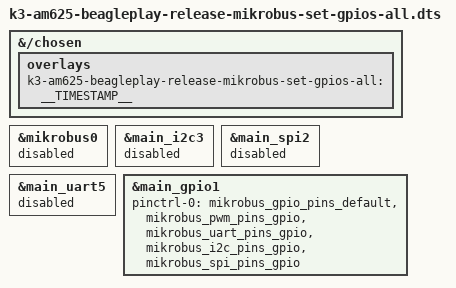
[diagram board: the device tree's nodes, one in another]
// SPDX-License-Identifier: GPL-2.0
/*
 * DT Overlay for disabling mikrobus device and reassigning pins to default options
 *
 * Copyright (C) 2023 Texas Instruments Incorporated - https://www.ti.com/
 *
 * Signal maps (GPIO Signal names to GPIO Signal (GPIO1 == 601000.gpio)
 * MIKROBUS_GPIO1_7  -> GPIO1_7
 * MIKROBUS_GPIO1_8  -> GPIO1_8
 * MIKROBUS_GPIO1_9  -> GPIO1_9
 * MIKROBUS_GPIO1_10 -> GPIO1_10
 * MIKROBUS_GPIO1_11 -> GPIO1_11
 * MIKROBUS_GPIO1_12 -> GPIO1_12
 * MIKROBUS_W1_GPIO0 -> GPIO1_13
 * MIKROBUS_GPIO1_14 -> GPIO1_14
 * MIKROBUS_GPIO1_22 -> GPIO1_22
 * MIKROBUS_GPIO1_23 -> GPIO1_23
 * MIKROBUS_GPIO1_24 -> GPIO1_24
 * MIKROBUS_GPIO1_25 -> GPIO1_25
 * MIKROBUS_GPIO1_22 -> GPIO1_22
 * MIKROBUS_GPIO1_23 -> GPIO1_23
 * MIKROBUS_GPIO1_24 -> GPIO1_24
 * MIKROBUS_GPIO1_25 -> GPIO1_25
 *
 * Mapped to Signals, these look as follows ("GPIO Mode" is set by this overlay):
 *
 * GPIO       Native        Pin                                    Pin   Native         GPIO
 * Mode       Function      Num     Legend              Legend     Num   Function       Mode
 * |                |        |       |                     |        |       |           |
 * |                |        |       v                     v        |       |           |
 * v                v        v     +--------------------------+     v       v           v
 * GPIO1_10  GPIO1_10  ------9-----+ AN                   PWM +-----8------ GPIO1_11    GPIO1_11
 *                                 |                          |
 * GPIO1_12  GPIO1_12  ------10----+ RST                  INT +-----7------ GPIO1_9     GPIO1_9
 *                                 |                          |
 * GPIO1_13  SPI2_CS0  ------11----+ CS                    RX +-----6------ UART5_RXD   GPIO1_24
 *                                 |                          |
 * GPIO1_14  SPI2_CLK  ------12----+ SCK                   TX +-----5------ UART5_TXD   GPIO1_25
 *                                 |                          |
 * GPIO1_7   SPI2_D0   ------13----+ MISO                 SCL +-----4------ I2C3_SCL    GPIO1_22
 *                                 |                          |
 * GPIO1_8   SPI2_D1   ------14----+ MOSI                 SDA +-----3------ I2C3_SDA    GPIO1_23
 *                                 |                          |
 *                     ------15----+ +3.3V                +5V +-----2------
 *                                 |                          |
 *                     ------16----+ GND2                GND1 +-----1------
 *                                 +--------------------------+
 */

/dts-v1/;
/plugin/;

&{/chosen} {
	overlays {
		k3-am625-beagleplay-release-mikrobus-set-gpios-all = __TIMESTAMP__;
	};
};

&mikrobus0 {
	status = "disabled";
};

/*
 * Disable all default peripherals for Mikrobus,
 * of depending on mikrobus driver to select
 */

&main_i2c3 {
	status = "disabled";
};

&main_spi2 {
	status = "disabled";
};

&main_uart5 {
	status = "disabled";
};

/* Mux everything as GPIOs.. */
&main_gpio1 {
	pinctrl-names = "default";
	pinctrl-0 = <&mikrobus_gpio_pins_default>, <&mikrobus_pwm_pins_gpio>,
		<&mikrobus_uart_pins_gpio>, <&mikrobus_i2c_pins_gpio>,
		<&mikrobus_spi_pins_gpio>;

};
